# ESP32S31_RADIO register map
Vendor: Espressif; Series: ESP32-S31; File version: 3.52
Registers are 32-bit, read-write, no defined reset value unless marked. A register's access mark holds for its fields unless they carry their own. Offsets are from the block's base; [hi:lo] are bit positions.

## HP_SYS_CLKRST_RADIO — Route-owned high-power system clock/reset words shared by the reviewed Wi-Fi, Bluetooth and IEEE 802.15.4 lifecycles. Unrelated HP_SYS_CLKRST words remain platform-owned.
Base 0x20587000
0x40 MODEM_CTRL0 reset 0x1 — Modem control/register-bus clock gate.
  [0] MODEM_CLK_EN — Modem control/register-bus clock enable.
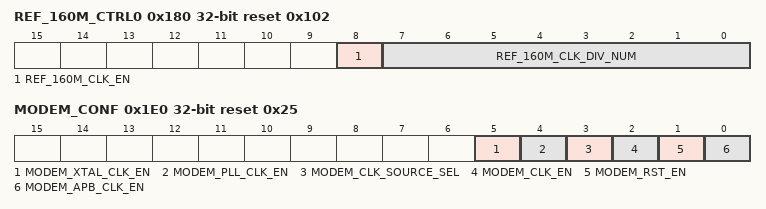
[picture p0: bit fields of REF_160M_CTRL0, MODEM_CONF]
0x180 REF_160M_CTRL0 reset 0x102 — 160 MHz reference divider and clock gate.
  [8] REF_160M_CLK_EN — 160 MHz reference clock gate shared by the radio lifecycles.
  [7:0] REF_160M_CLK_DIV_NUM — 160 MHz reference divider programmed by the platform clock tree.
    2=FIXED_480MHZ_SOURCE (Divider image two programmed by official ESP-HAL for the fixed 480 MHz BBPLL source.)
0x1E0 MODEM_CONF reset 0x25 — Modem APB, reset and source-clock configuration.
  [5] MODEM_XTAL_CLK_EN — Modem crystal clock enable.
  [4] MODEM_PLL_CLK_EN — Modem PLL clock enable.
  [3] MODEM_CLK_SOURCE_SEL — Modem source-clock selector.
  [2] MODEM_CLK_EN — Modem source-clock enable.
  [1] MODEM_RST_EN — Modem subsystem reset assertion.
  [0] MODEM_APB_CLK_EN — Modem APB clock enable.

## MODEM_LPCON_SHARED_CLOCK — Role-neutral MODEM_LPCON clock-map, gate and low-power selector registers shared by the exclusive Wi-Fi, Bluetooth and IEEE 802.15.4 routes.
Base 0x2010F000
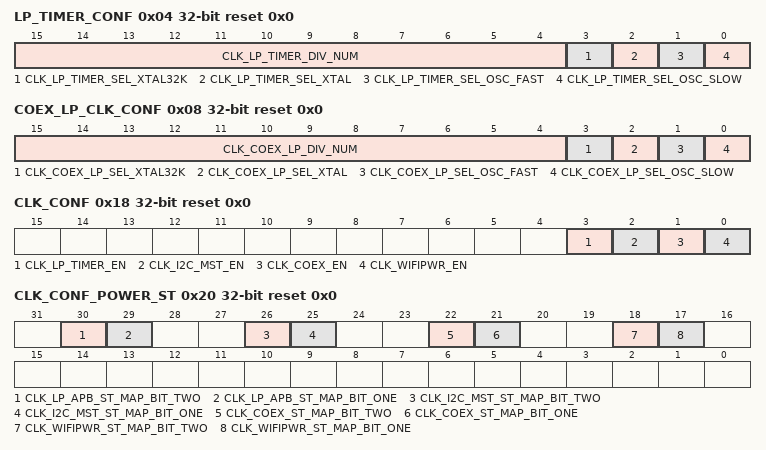
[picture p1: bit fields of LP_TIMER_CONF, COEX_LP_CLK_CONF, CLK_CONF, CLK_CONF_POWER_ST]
0x04 LP_TIMER_CONF reset 0x0 — Bluetooth low-power timer source selector and twelve-bit divider.
  [15:4] CLK_LP_TIMER_DIV_NUM — Twelve-bit low-power timer divider image.
  [3] CLK_LP_TIMER_SEL_XTAL32K — Select the 32 kHz crystal clock.
  [2] CLK_LP_TIMER_SEL_XTAL — Select the crystal clock.
  [1] CLK_LP_TIMER_SEL_OSC_FAST — Select the fast oscillator.
  [0] CLK_LP_TIMER_SEL_OSC_SLOW — Select the slow oscillator.
0x08 COEX_LP_CLK_CONF reset 0x0 — Coexistence low-power source selector and twelve-bit divider sampled by the coexistence time conversion.
  [15:4] CLK_COEX_LP_DIV_NUM — Twelve-bit coexistence low-power clock divider image.
  [3] CLK_COEX_LP_SEL_XTAL32K — Select the 32 kHz crystal clock.
  [2] CLK_COEX_LP_SEL_XTAL — Select the crystal clock.
  [1] CLK_COEX_LP_SEL_OSC_FAST — Select the fast oscillator.
  [0] CLK_COEX_LP_SEL_OSC_SLOW — Select the slow oscillator.
0x18 CLK_CONF reset 0x0 — Shared MODEM_LPCON clock gates used by radio lifecycles.
  [3] CLK_LP_TIMER_EN — Bluetooth low-power timer clock gate.
  [2] CLK_I2C_MST_EN — PHY I2C master clock gate.
  [1] CLK_COEX_EN — Coexistence clock gate.
  [0] CLK_WIFIPWR_EN — Wi-Fi power clock gate.
0x20 CLK_CONF_POWER_ST reset 0x0 — Four shared clock power-state map fields programmed with the reviewed active-state image.
  [30] CLK_LP_APB_ST_MAP_BIT_TWO — Bit two of the low-power APB clock state map, set by the reviewed shared active-state initialization.
  [29] CLK_LP_APB_ST_MAP_BIT_ONE — Bit one of the low-power APB clock state map, set by the reviewed shared active-state initialization.
  [26] CLK_I2C_MST_ST_MAP_BIT_TWO — Bit two of the PHY-I2C-master clock state map, set by the reviewed shared active-state initialization.
  [25] CLK_I2C_MST_ST_MAP_BIT_ONE — Bit one of the PHY-I2C-master clock state map, set by the reviewed shared active-state initialization.
  [22] CLK_COEX_ST_MAP_BIT_TWO — Bit two of the coexistence clock state map, set by the reviewed shared active-state initialization.
  [21] CLK_COEX_ST_MAP_BIT_ONE — Bit one of the coexistence clock state map, set by the reviewed shared active-state initialization.
  [18] CLK_WIFIPWR_ST_MAP_BIT_TWO — Bit two of the Wi-Fi-power clock state map, set by the reviewed shared active-state initialization.
  [17] CLK_WIFIPWR_ST_MAP_BIT_ONE — Bit one of the Wi-Fi-power clock state map, set by the reviewed shared active-state initialization.
